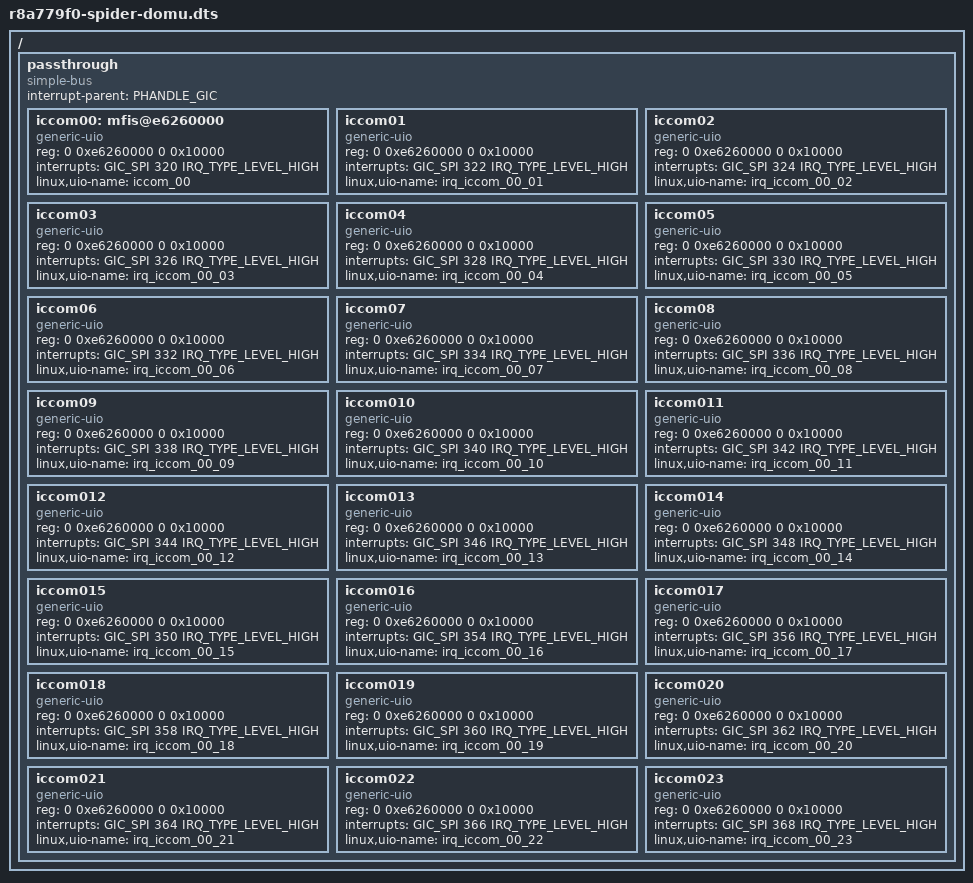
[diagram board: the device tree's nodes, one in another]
/dts-v1/;

#include <dt-bindings/interrupt-controller/arm-gic.h>

/*
 * The device tree compiler (DTC) is allocating the phandle from 1 to
 * onwards. Reserve a high value for the GIC phandle.
 */
#define PHANDLE_GIC (65000)

/ {
	#address-cells = <2>;
	#size-cells = <2>;

	passthrough {
		compatible = "simple-bus";
		ranges;

		#address-cells = <2>;
		#size-cells = <2>;

		/* This must point to Xen interrupt-parent. */
		interrupt-parent = <PHANDLE_GIC>;

		iccom00: mfis@e6260000 {
			compatible = "generic-uio";
			reg = <0 0xe6260000 0 0x10000>;
			interrupts = <GIC_SPI 320 IRQ_TYPE_LEVEL_HIGH>;
			linux,uio-name = "iccom_00";
		};

		iccom01 {
			compatible = "generic-uio";
			reg = <0 0xe6260000 0 0x10000>;
			interrupts = <GIC_SPI 322 IRQ_TYPE_LEVEL_HIGH>;
			linux,uio-name = "irq_iccom_00_01";
		};

		iccom02 {
			compatible = "generic-uio";
			reg = <0 0xe6260000 0 0x10000>;
			interrupts = <GIC_SPI 324 IRQ_TYPE_LEVEL_HIGH>;
			linux,uio-name = "irq_iccom_00_02";
		};

		iccom03 {
			compatible = "generic-uio";
			reg = <0 0xe6260000 0 0x10000>;
			interrupts = <GIC_SPI 326 IRQ_TYPE_LEVEL_HIGH>;
			linux,uio-name = "irq_iccom_00_03";
		};

		iccom04 {
			compatible = "generic-uio";
			reg = <0 0xe6260000 0 0x10000>;
			interrupts = <GIC_SPI 328 IRQ_TYPE_LEVEL_HIGH>;
			linux,uio-name = "irq_iccom_00_04";
		};

		iccom05 {
			compatible = "generic-uio";
			reg = <0 0xe6260000 0 0x10000>;
			interrupts = <GIC_SPI 330 IRQ_TYPE_LEVEL_HIGH>;
			linux,uio-name = "irq_iccom_00_05";
		};

		iccom06 {
			compatible = "generic-uio";
			reg = <0 0xe6260000 0 0x10000>;
			interrupts = <GIC_SPI 332 IRQ_TYPE_LEVEL_HIGH>;
			linux,uio-name = "irq_iccom_00_06";
		};

		iccom07 {
			compatible = "generic-uio";
			reg = <0 0xe6260000 0 0x10000>;
			interrupts = <GIC_SPI 334 IRQ_TYPE_LEVEL_HIGH>;
			linux,uio-name = "irq_iccom_00_07";
		};

		iccom08 {
			compatible = "generic-uio";
			reg = <0 0xe6260000 0 0x10000>;
			interrupts = <GIC_SPI 336 IRQ_TYPE_LEVEL_HIGH>;
			linux,uio-name = "irq_iccom_00_08";
		};

		iccom09 {
			compatible = "generic-uio";
			reg = <0 0xe6260000 0 0x10000>;
			interrupts = <GIC_SPI 338 IRQ_TYPE_LEVEL_HIGH>;
			linux,uio-name = "irq_iccom_00_09";
		};

		iccom010 {
			compatible = "generic-uio";
			reg = <0 0xe6260000 0 0x10000>;
			interrupts = <GIC_SPI 340 IRQ_TYPE_LEVEL_HIGH>;
			linux,uio-name = "irq_iccom_00_10";
		};


		iccom011 {
			compatible = "generic-uio";
			reg = <0 0xe6260000 0 0x10000>;
			interrupts = <GIC_SPI 342 IRQ_TYPE_LEVEL_HIGH>;
			linux,uio-name = "irq_iccom_00_11";
		};

		iccom012 {
			compatible = "generic-uio";
			reg = <0 0xe6260000 0 0x10000>;
			interrupts = <GIC_SPI 344 IRQ_TYPE_LEVEL_HIGH>;
			linux,uio-name = "irq_iccom_00_12";
		};

		iccom013 {
			compatible = "generic-uio";
			reg = <0 0xe6260000 0 0x10000>;
			interrupts = <GIC_SPI 346 IRQ_TYPE_LEVEL_HIGH>;
			linux,uio-name = "irq_iccom_00_13";
		};

		iccom014 {
			compatible = "generic-uio";
			reg = <0 0xe6260000 0 0x10000>;
			interrupts = <GIC_SPI 348 IRQ_TYPE_LEVEL_HIGH>;
			linux,uio-name = "irq_iccom_00_14";
		};

		iccom015 {
			compatible = "generic-uio";
			reg = <0 0xe6260000 0 0x10000>;
			interrupts = <GIC_SPI 350 IRQ_TYPE_LEVEL_HIGH>;
			linux,uio-name = "irq_iccom_00_15";
		};
		iccom016 {
			compatible = "generic-uio";
			reg = <0 0xe6260000 0 0x10000>;
			interrupts = <GIC_SPI 354 IRQ_TYPE_LEVEL_HIGH>;
			linux,uio-name = "irq_iccom_00_16";
		};

		iccom017 {
			compatible = "generic-uio";
			reg = <0 0xe6260000 0 0x10000>;
			interrupts = <GIC_SPI 356 IRQ_TYPE_LEVEL_HIGH>;
			linux,uio-name = "irq_iccom_00_17";
		};

		iccom018 {
			compatible = "generic-uio";
			reg = <0 0xe6260000 0 0x10000>;
			interrupts = <GIC_SPI 358 IRQ_TYPE_LEVEL_HIGH>;
			linux,uio-name = "irq_iccom_00_18";
		};

		iccom019 {
			compatible = "generic-uio";
			reg = <0 0xe6260000 0 0x10000>;
			interrupts = <GIC_SPI 360 IRQ_TYPE_LEVEL_HIGH>;
			linux,uio-name = "irq_iccom_00_19";
		};

		iccom020 {
			compatible = "generic-uio";
			reg = <0 0xe6260000 0 0x10000>;
			interrupts = <GIC_SPI 362 IRQ_TYPE_LEVEL_HIGH>;
			linux,uio-name = "irq_iccom_00_20";
		};

		iccom021 {
			compatible = "generic-uio";
			reg = <0 0xe6260000 0 0x10000>;
			interrupts = <GIC_SPI 364 IRQ_TYPE_LEVEL_HIGH>;
			linux,uio-name = "irq_iccom_00_21";
		};

		iccom022 {
			compatible = "generic-uio";
			reg = <0 0xe6260000 0 0x10000>;
			interrupts = <GIC_SPI 366 IRQ_TYPE_LEVEL_HIGH>;
			linux,uio-name = "irq_iccom_00_22";
		};

		iccom023 {
			compatible = "generic-uio";
			reg = <0 0xe6260000 0 0x10000>;
			interrupts = <GIC_SPI 368 IRQ_TYPE_LEVEL_HIGH>;
			linux,uio-name = "irq_iccom_00_23";
		};
	};
};
